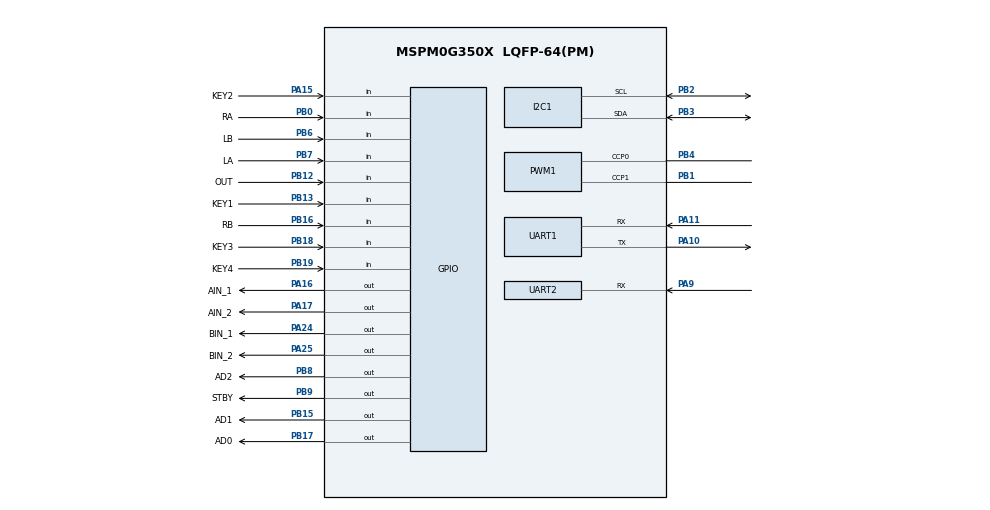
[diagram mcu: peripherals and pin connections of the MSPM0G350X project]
/**
 *
 * @cliArgs --device "MSPM0G350X" --part "Default" --package "LQFP-64(PM)" --product "mspm0_sdk@2.10.00.04"
 * @versions {"tool":"1.28.0+4696"}
 */

/**
 * Import the modules used in this configuration.
 */
const GPIO   = scripting.addModule("/ti/driverlib/GPIO", {}, false);
const GPIO1  = GPIO.addInstance();
const GPIO2  = GPIO.addInstance();
const GPIO3  = GPIO.addInstance();
const GPIO4  = GPIO.addInstance();
const I2C    = scripting.addModule("/ti/driverlib/I2C", {}, false);
const I2C1   = I2C.addInstance();
const PWM    = scripting.addModule("/ti/driverlib/PWM", {}, false);
const PWM1   = PWM.addInstance();
const SYSCTL = scripting.addModule("/ti/driverlib/SYSCTL");
const UART   = scripting.addModule("/ti/driverlib/UART", {}, false);
const UART1  = UART.addInstance();
const UART2  = UART.addInstance();

/**
 * Write custom configuration values to the imported modules.
 */
GPIO1.$name                         = "GPIO_MOTOR";
GPIO1.associatedPins.create(5);
GPIO1.associatedPins[0].$name       = "AIN_1";
GPIO1.associatedPins[0].pin.$assign = "PA16";
GPIO1.associatedPins[1].$name       = "AIN_2";
GPIO1.associatedPins[1].pin.$assign = "PA17";
GPIO1.associatedPins[2].$name       = "BIN_1";
GPIO1.associatedPins[2].pin.$assign = "PA24";
GPIO1.associatedPins[3].$name       = "BIN_2";
GPIO1.associatedPins[3].pin.$assign = "PA25";
GPIO1.associatedPins[4].$name       = "STBY";
GPIO1.associatedPins[4].pin.$assign = "PB9";

const Board = scripting.addModule("/ti/driverlib/Board", {}, false);

GPIO2.$name                              = "GPIO_IO";
GPIO2.associatedPins.create(4);
GPIO2.associatedPins[0].$name            = "KEY1";
GPIO2.associatedPins[0].direction        = "INPUT";
GPIO2.associatedPins[0].internalResistor = "PULL_UP";
GPIO2.associatedPins[0].pin.$assign      = "PB13";
GPIO2.associatedPins[1].$name            = "KEY2";
GPIO2.associatedPins[1].internalResistor = "PULL_UP";
GPIO2.associatedPins[1].direction        = "INPUT";
GPIO2.associatedPins[1].pin.$assign      = "PA15";
GPIO2.associatedPins[2].$name            = "KEY3";
GPIO2.associatedPins[2].direction        = "INPUT";
GPIO2.associatedPins[2].internalResistor = "PULL_UP";
GPIO2.associatedPins[2].pin.$assign      = "PB18";
GPIO2.associatedPins[3].$name            = "KEY4";
GPIO2.associatedPins[3].direction        = "INPUT";
GPIO2.associatedPins[3].internalResistor = "PULL_UP";
GPIO2.associatedPins[3].pin.$assign      = "PB19";

GPIO3.$name                              = "GPIO_AB";
GPIO3.associatedPins.create(4);
GPIO3.associatedPins[0].$name            = "LA";
GPIO3.associatedPins[0].direction        = "INPUT";
GPIO3.associatedPins[0].internalResistor = "PULL_UP";
GPIO3.associatedPins[0].interruptEn      = true;
GPIO3.associatedPins[0].polarity         = "RISE_FALL";
GPIO3.associatedPins[0].pin.$assign      = "PB7";
GPIO3.associatedPins[1].$name            = "LB";
GPIO3.associatedPins[1].direction        = "INPUT";
GPIO3.associatedPins[1].internalResistor = "PULL_UP";
GPIO3.associatedPins[1].pin.$assign      = "PB6";
GPIO3.associatedPins[2].$name            = "RA";
GPIO3.associatedPins[2].direction        = "INPUT";
GPIO3.associatedPins[2].internalResistor = "PULL_UP";
GPIO3.associatedPins[2].pin.$assign      = "PB0";
GPIO3.associatedPins[3].$name            = "RB";
GPIO3.associatedPins[3].direction        = "INPUT";
GPIO3.associatedPins[3].internalResistor = "PULL_UP";
GPIO3.associatedPins[3].pin.$assign      = "PB16";

GPIO4.$name                              = "GPIO_GRAY";
GPIO4.associatedPins.create(4);
GPIO4.associatedPins[0].$name            = "OUT";
GPIO4.associatedPins[0].direction        = "INPUT";
GPIO4.associatedPins[0].internalResistor = "PULL_UP";
GPIO4.associatedPins[0].pin.$assign      = "PB12";
GPIO4.associatedPins[1].$name            = "AD0";
GPIO4.associatedPins[1].pin.$assign      = "PB17";
GPIO4.associatedPins[2].$name            = "AD1";
GPIO4.associatedPins[2].pin.$assign      = "PB15";
GPIO4.associatedPins[3].$name            = "AD2";
GPIO4.associatedPins[3].pin.$assign      = "PB8";

I2C1.$name                             = "I2C";
I2C1.basicEnableController             = true;
I2C1.basicControllerStandardBusSpeed   = "Fast";
I2C1.peripheral.sdaPin.$assign         = "PB3";
I2C1.peripheral.sclPin.$assign         = "PB2";
I2C1.sdaPinConfig.$name                = "ti_driverlib_gpio_GPIOPinGeneric0";
I2C1.sdaPinConfig.hideOutputInversion  = scripting.forceWrite(false);
I2C1.sdaPinConfig.onlyInternalResistor = scripting.forceWrite(false);
I2C1.sdaPinConfig.passedPeripheralType = scripting.forceWrite("Digital");
I2C1.sclPinConfig.$name                = "ti_driverlib_gpio_GPIOPinGeneric1";
I2C1.sclPinConfig.hideOutputInversion  = scripting.forceWrite(false);
I2C1.sclPinConfig.onlyInternalResistor = scripting.forceWrite(false);
I2C1.sclPinConfig.passedPeripheralType = scripting.forceWrite("Digital");

PWM1.$name                              = "PWM";
PWM1.timerCount                         = 2000;
PWM1.peripheral.ccp0Pin.$assign         = "PB4";
PWM1.peripheral.ccp1Pin.$assign         = "PB1";
PWM1.PWM_CHANNEL_0.$name                = "ti_driverlib_pwm_PWMTimerCC0";
PWM1.PWM_CHANNEL_1.$name                = "ti_driverlib_pwm_PWMTimerCC1";
PWM1.ccp0PinConfig.direction            = scripting.forceWrite("OUTPUT");
PWM1.ccp0PinConfig.hideOutputInversion  = scripting.forceWrite(false);
PWM1.ccp0PinConfig.onlyInternalResistor = scripting.forceWrite(false);
PWM1.ccp0PinConfig.passedPeripheralType = scripting.forceWrite("Digital");
PWM1.ccp0PinConfig.$name                = "ti_driverlib_gpio_GPIOPinGeneric4";
PWM1.ccp1PinConfig.direction            = scripting.forceWrite("OUTPUT");
PWM1.ccp1PinConfig.hideOutputInversion  = scripting.forceWrite(false);
PWM1.ccp1PinConfig.onlyInternalResistor = scripting.forceWrite(false);
PWM1.ccp1PinConfig.passedPeripheralType = scripting.forceWrite("Digital");
PWM1.ccp1PinConfig.$name                = "ti_driverlib_gpio_GPIOPinGeneric5";

SYSCTL.forceDefaultClkConfig = true;

UART1.$name                            = "UART_1";
UART1.targetBaudRate                   = 115200;
UART1.peripheral.$assign               = "UART0";
UART1.peripheral.rxPin.$assign         = "PA11";
UART1.peripheral.txPin.$assign         = "PA10";
UART1.txPinConfig.direction            = scripting.forceWrite("OUTPUT");
UART1.txPinConfig.hideOutputInversion  = scripting.forceWrite(false);
UART1.txPinConfig.onlyInternalResistor = scripting.forceWrite(false);
UART1.txPinConfig.passedPeripheralType = scripting.forceWrite("Digital");
UART1.txPinConfig.$name                = "ti_driverlib_gpio_GPIOPinGeneric6";
UART1.rxPinConfig.hideOutputInversion  = scripting.forceWrite(false);
UART1.rxPinConfig.onlyInternalResistor = scripting.forceWrite(false);
UART1.rxPinConfig.passedPeripheralType = scripting.forceWrite("Digital");
UART1.rxPinConfig.$name                = "ti_driverlib_gpio_GPIOPinGeneric7";

UART2.$name                    = "UART_0";
UART2.targetBaudRate           = 115200;
UART2.direction                = "RX";
UART2.rxPinConfig.$name        = "ti_driverlib_gpio_GPIOPinGeneric3";
UART2.peripheral.$assign       = "UART1";
UART2.peripheral.rxPin.$assign = "PA9";

/**
 * Pinmux solution for unlocked pins/peripherals. This ensures that minor changes to the automatic solver in a future
 * version of the tool will not impact the pinmux you originally saw.  These lines can be completely deleted in order to
 * re-solve from scratch.
 */
Board.peripheral.$suggestSolution          = "DEBUGSS";
Board.peripheral.swclkPin.$suggestSolution = "PA20";
Board.peripheral.swdioPin.$suggestSolution = "PA19";
I2C1.peripheral.$suggestSolution           = "I2C1";
PWM1.peripheral.$suggestSolution           = "TIMA1";
SYSCTL.peripheral.$suggestSolution         = "SYSCTL";
